VERSION ""

NS_ :

BS_:

BU_: GW_ABFD ADCU3_ABFD

BO_ 563 ADCU3A_IMU: 16 ADCU3_ABFD
 SG_ ADCU3A_RollRateVld : 120|1@1+ (1,0) [0|1] "" Vector__XXX
 SG_ ADCU3A_PitchRateVld : 121|1@1+ (1,0) [0|1] "" Vector__XXX
 SG_ ADCU3A_YawRateVld : 122|1@1+ (1,0) [0|1] "" Vector__XXX

BO_ 1523 ADCU3A_Test: 64 ADCU3_ABFD
 SG_ ADCU3A_LKASFltCod : 0|16@1+ (1,0) [0|65535] "" Vector__XXX
 SG_ ADCU3A_LKARunLvl : 16|3@1+ (1,0) [0|4] "" Vector__XXX
 SG_ ADCU3A_LKALatSt : 19|3@1+ (1,0) [0|4] "bit" Vector__XXX
 SG_ ADCU3A_LKALaneWidth : 24|8@1+ (0.01,0) [0|25] "m" Vector__XXX
 SG_ ADCU3A_LKALeftVeh2CentrLeftLane : 32|16@1- (0.00390625,0) [-127|128] "m" Vector__XXX
 SG_ ADCU3A_LKARightVeh2CentrtLane : 48|16@1- (0.00390625,0) [-127|128] "m" Vector__XXX
 SG_ ADCU3A_LKALgtdPwDst : 64|15@1+ (0.00390625,0) [0|127.996] "m" Vector__XXX
 SG_ ADCU3A_LKALeftLatPwDst : 80|16@1- (0.00390625,0) [-127|128] "m" Vector__XXX
 SG_ ADCU3A_LKARightLatPwDst : 96|16@1- (0.00390625,0) [-127|128] "m" Vector__XXX
 SG_ ADCU3A_LKACalcTarCrvt : 112|16@1- (9.8E-007,0.031999023) [-0.02|0.02] "1/m" Vector__XXX
 SG_ ADCU3A_BSDFaultCode : 128|16@1+ (1,0) [0|65535] "" Vector__XXX
 SG_ ADCU3A_DOWFaultCode : 144|16@1+ (1,0) [0|65535] "" Vector__XXX
 SG_ ADCU3A_ISLIFaultCode : 160|16@1+ (1,0) [0|65535] "" Vector__XXX
 SG_ ADCU3A_FCWInhibitNum : 176|16@1+ (1,0) [0|65535] "bit" Vector__XXX
 SG_ ADCU3A_FCWMode : 192|4@1+ (1,0) [0|15] "bit" Vector__XXX
 SG_ ADCU3A_FCW1Dist : 198|10@1+ (0.1,0) [0|100] "m" Vector__XXX
 SG_ ADCU3A_FCW2Dist : 208|10@1+ (0.1,0) [0|100] "m" Vector__XXX
 SG_ ADCU3A_FCW3Dist : 222|10@1+ (0.1,0) [0|100] "m" Vector__XXX
 SG_ ADCU3A_FCWAvoidAcc : 232|8@1+ (0.1,-10) [-10|10] "m/s^2" Vector__XXX
 SG_ ADCU3A_AEBInhibitNum : 240|16@1+ (1,0) [0|65535] "" Vector__XXX
 SG_ ADCU3A_AEBMode : 256|4@1+ (1,0) [0|15] "" Vector__XXX
 SG_ ADCU3A_AEBDist : 262|10@1+ (0.1,0) [0|100] "m" Vector__XXX
 SG_ ADCU3A_FCWCIP : 272|4@1+ (1,0) [0|15] "" Vector__XXX
 SG_ ADCU3A_FCWTargetID : 280|8@1+ (1,0) [0|255] "" Vector__XXX
 SG_ ADCU3A_FCWRelDisX : 288|11@1+ (0.1,0) [0|204.7] "m" Vector__XXX
 SG_ ADCU3A_FCWRelSpdX : 304|14@1+ (0.01,-81.92) [-81.92|81.91] "m/s" Vector__XXX
 SG_ ADCU3A_FCWOffset : 320|8@1+ (0.1,-12.7) [-12.7|12.8] "m" Vector__XXX
 SG_ ADCU3A_FCWRelDisY : 328|8@1+ (0.1,-12.7) [-12.7|12.8] "m" Vector__XXX
 SG_ ADCU3A_FCWRelSpdY : 336|8@1+ (0.1,-12.7) [-12.7|12.8] "m/s" Vector__XXX
 SG_ ADCU3A_AEBCIP : 344|4@1+ (1,0) [0|15] "" Vector__XXX
 SG_ ADCU3A_AEBTargetID : 352|8@1+ (1,0) [0|255] "" Vector__XXX
 SG_ ADCU3A_AEBRelDisX : 360|11@1+ (0.1,0) [0|204.7] "m" Vector__XXX
 SG_ ADCU3A_AEBRelSpdX : 376|14@1+ (0.01,-81.92) [-81.92|81.91] "m/s" Vector__XXX
 SG_ ADCU3A_AEBOffset : 392|8@1+ (0.1,-12.7) [-12.7|12.8] "m" Vector__XXX
 SG_ ADCU3A_AEBRelDisY : 400|8@1+ (0.1,-12.7) [-12.7|12.8] "m" Vector__XXX
 SG_ ADCU3A_AEBRelSpdY : 408|8@1+ (0.1,-12.7) [-12.7|12.8] "m/s" Vector__XXX

BO_ 2566877463 CDCU_BodyCtrl: 8 GW_ABFD
 SG_ CDCU_FrFogLgtSwt : 8|2@1+ (1,0) [0|3] ""  ADCU3_ABFD
 SG_ CDCU_ReFogLgtSwt : 10|2@1+ (1,0) [0|3] ""  ADCU3_ABFD

BO_ 1101 CDCU_St1: 16 GW_ABFD
 SG_ CDCU_VehSpdHMI : 32|13@1+ (0.1,0) [0|819.1] "km/h"  ADCU3_ABFD

BO_ 621 CDCU_ADCUCtrl: 16 GW_ABFD
 SG_ CDCU_ADCUCtrl_CRC : 0|16@1+ (1,0) [0|65535] ""  ADCU3_ABFD
 SG_ CDCU_ADCUCtrl_AC : 16|8@1+ (1,0) [0|255] ""  ADCU3_ABFD
 SG_ CDCU_FwdCllsnPrevnSwt : 24|1@1+ (1,0) [0|1] ""  ADCU3_ABFD
 SG_ CDCU_FwdCllsnPrevnMdSwt : 28|1@1+ (1,0) [0|1] ""  ADCU3_ABFD
 SG_ CDCU_FwdCllsnPrevnSnvtySet : 30|2@1+ (1,0) [0|3] ""  ADCU3_ABFD
 SG_ CDCU_ISLISwt : 32|1@1+ (1,0) [0|1] ""  ADCU3_ABFD
 SG_ CDCU_ISLISnvtySet : 34|5@1+ (1,-15) [-15|16] "km/h"  ADCU3_ABFD
 SG_ CDCU_LKASSwt : 42|1@1+ (1,0) [0|1] ""  ADCU3_ABFD
 SG_ CDCU_PACCSwt : 46|1@1+ (1,0) [0|1] ""  ADCU3_ABFD
 SG_ CDCU_HNASwt : 50|1@1+ (1,0) [0|1] ""  ADCU3_ABFD
 SG_ CDCU_FctLrngModSwt : 58|1@1+ (1,0) [0|1] ""  ADCU3_ABFD
 SG_ CDCU_FctLrngModSt : 60|2@1+ (1,0) [0|3] ""  ADCU3_ABFD
 SG_ CDCU_FctLrngModRes : 62|2@1+ (1,0) [0|3] ""  ADCU3_ABFD
 SG_ CDCU_HISSnsrAutoClrSwt : 64|1@1+ (1,0) [0|1] ""  ADCU3_ABFD
 SG_ CDCU_HISSnsrClrSwt : 66|4@1+ (1,0) [0|15] ""  ADCU3_ABFD
 SG_ CDCU_BSDSwt : 72|1@1+ (1,0) [0|1] ""  ADCU3_ABFD
 SG_ CDCU_DOWSwt : 73|1@1+ (1,0) [0|1] ""  ADCU3_ABFD
 SG_ CDCU_LKASFuncSetSwt : 76|1@1+ (1,0) [0|1] ""  ADCU3_ABFD
 SG_ CDCU_LKASWarnFormSetSwt : 77|2@1+ (1,0) [0|3] ""  ADCU3_ABFD
 SG_ CDCU_LKASSnvtySetSwt : 80|2@1+ (1,0) [0|3] ""  ADCU3_ABFD
 SG_ CDCU_LaneChgSwt : 82|1@1+ (1,0) [0|1] ""  ADCU3_ABFD
 SG_ CDCU_AutoLaneChgCfm : 83|1@1+ (1,0) [0|1] ""  ADCU3_ABFD
 SG_ CDCU_AutoLaneChgRmnSet : 84|2@1+ (1,0) [0|3] ""  ADCU3_ABFD
 SG_ CDCU_AutoLaneChgSet : 86|2@1+ (1,0) [0|3] ""  ADCU3_ABFD
 SG_ CDCU_NightVisnSwt : 88|1@1+ (1,0) [0|1] ""  ADCU3_ABFD
 SG_ CDCU_NightVisnWarnModReq : 90|2@1+ (1,0) [0|3] ""  ADCU3_ABFD

BO_ 1230 CDCU_DMSSt: 16 GW_ABFD
 SG_ CDCU_DMSSet_CRC : 0|16@1+ (1,0) [0|65535] ""  ADCU3_ABFD
 SG_ CDCU_DMSSet_AC : 16|8@1+ (1,0) [0|255] ""  ADCU3_ABFD
 SG_ CDCU_DMSSt : 24|3@1+ (1,0) [0|7] ""  ADCU3_ABFD
 SG_ CDCU_DMSErrSt : 64|2@1+ (1,0) [0|3] ""  ADCU3_ABFD
 SG_ CDCU_DMSWarnSwt : 66|1@1+ (1,0) [0|1] ""  ADCU3_ABFD
 SG_ CDCU_DrvrFatgWarn : 68|2@1+ (1,0) [0|3] ""  ADCU3_ABFD
 SG_ CDCU_AbnoActnDtcn : 72|3@1+ (1,0) [0|7] ""  ADCU3_ABFD
 SG_ CDCU_AbnoEmtnDtcn : 75|3@1+ (1,0) [0|7] ""  ADCU3_ABFD
 SG_ CDCU_DistrctnWarn : 80|3@1+ (1,0) [0|7] ""  ADCU3_ABFD

BO_ 2566832407 CDCU_VDHR: 8 GW_ABFD
 SG_ CDCU_VehTotDst : 0|32@1+ (1,0) [0|10000000] "kM"  ADCU3_ABFD

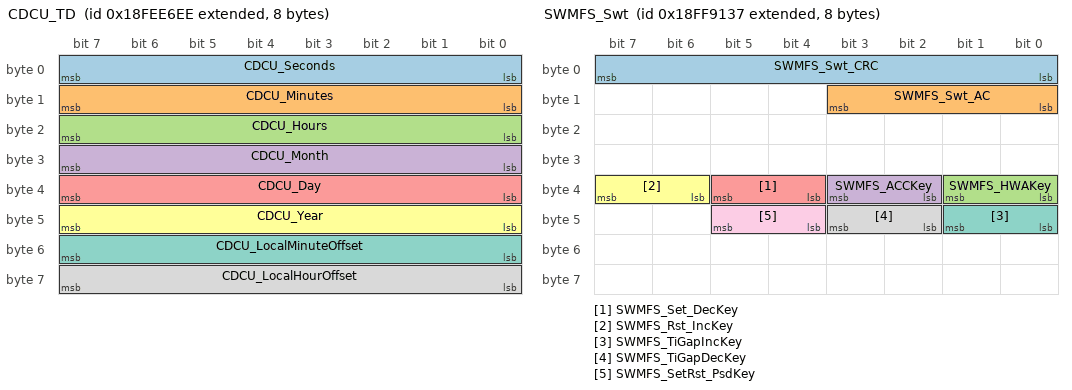
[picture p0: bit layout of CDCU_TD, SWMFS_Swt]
BO_ 2566842094 CDCU_TD: 8 GW_ABFD
 SG_ CDCU_Seconds : 0|8@1+ (0.25,0) [0|59.75] "s"  ADCU3_ABFD
 SG_ CDCU_Minutes : 8|8@1+ (1,0) [0|59] "min"  ADCU3_ABFD
 SG_ CDCU_Hours : 16|8@1+ (1,0) [0|23] "h"  ADCU3_ABFD
 SG_ CDCU_Month : 24|8@1+ (1,0) [1|12] "month"  ADCU3_ABFD
 SG_ CDCU_Day : 32|8@1+ (0.25,0) [0.25|31.75] "day"  ADCU3_ABFD
 SG_ CDCU_Year : 40|8@1+ (1,1985) [1985|2235] "year"  ADCU3_ABFD
 SG_ CDCU_LocalMinuteOffset : 48|8@1+ (1,-59) [-59|59] "min"  ADCU3_ABFD
 SG_ CDCU_LocalHourOffset : 56|8@1+ (1,-23) [-23|23] "h"  ADCU3_ABFD

BO_ 2566885687 SWMFS_Swt: 8 GW_ABFD
 SG_ SWMFS_Swt_CRC : 0|8@1+ (1,0) [0|255] ""  ADCU3_ABFD
 SG_ SWMFS_Swt_AC : 8|4@1+ (1,0) [0|14] ""  ADCU3_ABFD
 SG_ SWMFS_HWAKey : 32|2@1+ (1,0) [0|3] ""  ADCU3_ABFD
 SG_ SWMFS_ACCKey : 34|2@1+ (1,0) [0|3] ""  ADCU3_ABFD
 SG_ SWMFS_Set_DecKey : 36|2@1+ (1,0) [0|3] ""  ADCU3_ABFD
 SG_ SWMFS_Rst_IncKey : 38|2@1+ (1,0) [0|3] ""  ADCU3_ABFD
 SG_ SWMFS_TiGapIncKey : 40|2@1+ (1,0) [0|3] ""  ADCU3_ABFD
 SG_ SWMFS_TiGapDecKey : 42|2@1+ (1,0) [0|3] ""  ADCU3_ABFD
 SG_ SWMFS_SetRst_PsdKey : 44|2@1+ (1,0) [0|3] ""  ADCU3_ABFD

BO_ 2015 StdFunc_DiagReq: 8 GW_ABFD
 SG_ StdFunc_DiagReqData : 0|64@1+ (1,0) [0|9.22337203685477E+018] ""  ADCU3_ABFD

BO_ 1065 TBOX_RmtCtrl2: 16 GW_ABFD

BO_ 1793 FR_DiagReq: 64 GW_ABFD

BO_ 1801 FR_DiagResp: 64 ADCU3_ABFD

BO_ 1926 CR_FL_DiagReq: 64 GW_ABFD

BO_ 1934 CR_FL_DiagResp: 64 ADCU3_ABFD

BO_ 1927 CR_FR_DiagReq: 64 GW_ABFD

BO_ 1935 CR_FR_DiagResp: 64 ADCU3_ABFD

BO_ 1936 CR_RL_DiagReq: 64 GW_ABFD

BO_ 1944 CR_RL_DiagResp: 64 ADCU3_ABFD

BO_ 1925 CR_RR_DiagReq: 64 GW_ABFD

BO_ 1933 CR_RR_DiagResp: 64 ADCU3_ABFD

CM_ SG_ 563 ADCU3A_RollRateVld "Roll Rate Validity
IMU侧倾角速度有效性";
CM_ SG_ 563 ADCU3A_PitchRateVld "Pitch Rate Validity
IMU俯仰角速度有效性";
CM_ SG_ 563 ADCU3A_YawRateVld "Yaw Rate Validity
IMU横摆角速度有效性";
CM_ SG_ 1523 ADCU3A_LKASFltCod "LKAS fault code
LKAS故障码";
CM_ SG_ 1523 ADCU3A_LKARunLvl "LKA operation status level
LKA运行状态等级";
CM_ SG_ 1523 ADCU3A_LKALatSt "Vehicle lateral motion state
车辆横向运动状态";
CM_ SG_ 1523 ADCU3A_LKALaneWidth "Lane width
车道宽度";
CM_ SG_ 1523 ADCU3A_LKALeftVeh2CentrLeftLane "Distance between vehicle and lane center calculated by left lane line
从左侧车道线计算的车辆距车道中心位置";
CM_ SG_ 1523 ADCU3A_LKARightVeh2CentrtLane "从右侧车道线计算的车辆距车道中心位置";
CM_ SG_ 1523 ADCU3A_LKALgtdPwDst "预瞄点纵向距离";
CM_ SG_ 1523 ADCU3A_LKALeftLatPwDst "从左侧车道线计算的预瞄点横向距离";
CM_ SG_ 1523 ADCU3A_LKARightLatPwDst "从右侧车道线计算的预瞄点横向距离";
CM_ SG_ 1523 ADCU3A_LKACalcTarCrvt "计算的目标曲率";
CM_ SG_ 1523 ADCU3A_BSDFaultCode "BSD Fault Code
BSD故障码";
CM_ SG_ 1523 ADCU3A_DOWFaultCode "DOW Fault Code
DOW故障码";
CM_ SG_ 1523 ADCU3A_ISLIFaultCode "ISLI Fault Code
ISLI故障码";
CM_ SG_ 1523 ADCU3A_FCWInhibitNum "FCW抑制代码";
CM_ SG_ 1523 ADCU3A_FCWMode "FCW工作模式";
CM_ SG_ 1523 ADCU3A_FCW1Dist "FCW一级报警距离";
CM_ SG_ 1523 ADCU3A_FCW2Dist "FCW二级报警距离";
CM_ SG_ 1523 ADCU3A_FCW3Dist "FCW三级报警距离";
CM_ SG_ 1523 ADCU3A_FCWAvoidAcc "避撞减速度";
CM_ SG_ 1523 ADCU3A_AEBInhibitNum "AEB抑制代码";
CM_ SG_ 1523 ADCU3A_AEBMode "AEB工作模式";
CM_ SG_ 1523 ADCU3A_AEBDist "AEB作用距离";
CM_ SG_ 1523 ADCU3A_FCWCIP "FCW目标序号";
CM_ SG_ 1523 ADCU3A_FCWTargetID "FCW目标ID";
CM_ SG_ 1523 ADCU3A_FCWRelDisX "FCW目标纵向相对距离";
CM_ SG_ 1523 ADCU3A_FCWRelSpdX "FCW目标纵向相对速度";
CM_ SG_ 1523 ADCU3A_FCWOffset "FCW目标横向偏移";
CM_ SG_ 1523 ADCU3A_FCWRelDisY "FCW目标横向相对距离";
CM_ SG_ 1523 ADCU3A_FCWRelSpdY "FCW目标横向相对速度";
CM_ SG_ 1523 ADCU3A_AEBCIP "AEB目标序号";
CM_ SG_ 1523 ADCU3A_AEBTargetID "AEB目标ID";
CM_ SG_ 1523 ADCU3A_AEBRelDisX "AEB目标纵向相对距离";
CM_ SG_ 1523 ADCU3A_AEBRelSpdX "AEB目标纵向相对速度";
CM_ SG_ 1523 ADCU3A_AEBOffset "AEB目标横向偏移";
CM_ SG_ 1523 ADCU3A_AEBRelDisY "AEB目标横向相对距离";
CM_ SG_ 1523 ADCU3A_AEBRelSpdY "AEB目标横向相对速度";
CM_ SG_ 2566877463 CDCU_FrFogLgtSwt "Front fog light switch command
前雾灯开关";
CM_ SG_ 2566877463 CDCU_ReFogLgtSwt "Rear fog light switch command
后雾灯开关";
CM_ SG_ 1101 CDCU_VehSpdHMI "Vehicle Speed on HMI 
显示车速";
CM_ SG_ 621 CDCU_ADCUCtrl_CRC "CRC16";
CM_ SG_ 621 CDCU_ADCUCtrl_AC "Alive Counter";
CM_ SG_ 621 CDCU_FwdCllsnPrevnSwt "Forward Collision Prevention  Switch
前向防撞辅助开关";
CM_ SG_ 621 CDCU_FwdCllsnPrevnMdSwt "Forward Collision Prevention Mode Switch
前向防撞辅助模式";
CM_ SG_ 621 CDCU_FwdCllsnPrevnSnvtySet "Forward Collision Prevention Sensitivity Set
前向防撞辅助灵敏度设置";
CM_ SG_ 621 CDCU_ISLISwt "ISLI switch
ISLI功能开关";
CM_ SG_ 621 CDCU_ISLISnvtySet "ISLI sensitivity set
ISLI功能灵敏设置";
CM_ SG_ 621 CDCU_LKASSwt "LKAS switch
LKAS功能开关";
CM_ SG_ 621 CDCU_PACCSwt "PACC switch
PACC功能开关";
CM_ SG_ 621 CDCU_HNASwt "HNA switch
高速公路导航辅助功能开关";
CM_ SG_ 621 CDCU_FctLrngModSwt "Function learning mode switch
功能学习模式开关";
CM_ SG_ 621 CDCU_FctLrngModSt "Function learning mode state
功能学习模式状态";
CM_ SG_ 621 CDCU_FctLrngModRes "Function learning mode result
功能学习模式结果";
CM_ SG_ 621 CDCU_HISSnsrAutoClrSwt "HIS sensor auto clear switch
智能驾驶自动清洗开关";
CM_ SG_ 621 CDCU_HISSnsrClrSwt "HIS sensor clear switch
智能驾驶传感器清洗开关";
CM_ SG_ 621 CDCU_BSDSwt "BSD switch
BSD功能开关";
CM_ SG_ 621 CDCU_DOWSwt "DOW switch
DOW功能开关";
CM_ SG_ 621 CDCU_LKASFuncSetSwt "LKAS Function Set
LKAS辅助等级设置";
CM_ SG_ 621 CDCU_LKASWarnFormSetSwt "LKAS Warnning Form Set
LKAS提醒方式设置";
CM_ SG_ 621 CDCU_LKASSnvtySetSwt "LKAS Snvty Set
LKAS灵敏度设置";
CM_ SG_ 621 CDCU_LaneChgSwt "Lane change auxiliary switch
变道辅助开关";
CM_ SG_ 621 CDCU_AutoLaneChgCfm "Automatic lane change confirmation switch
自动变道确认开关反馈";
CM_ SG_ 621 CDCU_AutoLaneChgRmnSet "Lane change reminder setting
变道提醒设置";
CM_ SG_ 621 CDCU_AutoLaneChgSet "Lane change style setting
变道风格设置反馈";
CM_ SG_ 621 CDCU_NightVisnSwt "Night Vision Switch
夜视辅助开关";
CM_ SG_ 621 CDCU_NightVisnWarnModReq "Night Vision Warning Mode Request
夜视辅助报警模式请求";
CM_ SG_ 1230 CDCU_DMSSet_CRC "CRC16";
CM_ SG_ 1230 CDCU_DMSSet_AC "Alive Counter";
CM_ SG_ 1230 CDCU_DMSSt "DMS system state
DMS系统状态";
CM_ SG_ 1230 CDCU_DMSErrSt "DMS fault state
DMS故障状态";
CM_ SG_ 1230 CDCU_DMSWarnSwt "DMS warning switch state (reserved)
DMS报警开关状态（预留）";
CM_ SG_ 1230 CDCU_DrvrFatgWarn "Driver fatigue warn
主驾疲劳报警";
CM_ SG_ 1230 CDCU_AbnoActnDtcn "Driver abnormal behavior detected
主驾异常行为监测";
CM_ SG_ 1230 CDCU_AbnoEmtnDtcn "Driver abnormal emotion detected
主驾异常情绪监测";
CM_ SG_ 1230 CDCU_DistrctnWarn "Driver attention warning
主驾注意力报警";
CM_ SG_ 2566832407 CDCU_VehTotDst "Vehicle total distance
整车总里程";
CM_ SG_ 2566842094 CDCU_Seconds "Seconds
秒";
CM_ SG_ 2566842094 CDCU_Minutes "Minutes
分";
CM_ SG_ 2566842094 CDCU_Hours "Hours
时";
CM_ SG_ 2566842094 CDCU_Month "Month
月";
CM_ SG_ 2566842094 CDCU_Day "Day
日";
CM_ SG_ 2566842094 CDCU_Year "Year
年";
CM_ SG_ 2566842094 CDCU_LocalMinuteOffset "Local minute offset
本地分钟偏差";
CM_ SG_ 2566842094 CDCU_LocalHourOffset "Local hour offset
本地小时偏移";
CM_ SG_ 2566885687 SWMFS_Swt_CRC "CRC8";
CM_ SG_ 2566885687 SWMFS_Swt_AC "Alive Counter";
CM_ SG_ 2566885687 SWMFS_HWAKey "HWA switch
HWA开关";
CM_ SG_ 2566885687 SWMFS_ACCKey "ACC switch
ACC开关";
CM_ SG_ 2566885687 SWMFS_Set_DecKey "Set- switch
Set-开关";
CM_ SG_ 2566885687 SWMFS_Rst_IncKey "Reset+ switch
Reset+开关";
CM_ SG_ 2566885687 SWMFS_TiGapIncKey "Time gap increase switch
时距加开关";
CM_ SG_ 2566885687 SWMFS_TiGapDecKey "Time gap decrease switch
时距减开关";
CM_ SG_ 2566885687 SWMFS_SetRst_PsdKey "Intelligent speed limit confirmation switch
智能限速确认开关";
CM_ BO_ 2015 "OBD接口通过以太网TX或TBOX通过T1发送到GW，GW转换为CAN(FD)或以太网T1后向相应网段发送";
CM_ SG_ 2015 StdFunc_DiagReqData "诊断数据";
BA_DEF_ BO_  "DiagState" ENUM  "No","Yes";
BA_DEF_ BO_  "GenMsgSendType" ENUM  "Cyclic","Event","IfActive","CE","CA","NoMsgSendType";
BA_DEF_ BO_  "GenMsgCycleTime" INT 0 0;
BA_DEF_ SG_  "GenSigSendType" ENUM  "Cyclic","OnChange","OnWrite","IfActive","OnChangeWithRepetition","OnWriteWithRepetition","IfActiveWithRepetition","NoSigSendType","OnChangeAndIfActive","OnChangeAndIfActiveWithRepetition","CA","CE","Event";
BA_DEF_ SG_  "GenSigStartValue" INT 0 0;
BA_DEF_ BO_  "GenMsgCycleTimeFast" INT 0 0;
BA_DEF_ BO_  "CANFD_BRS" ENUM  "0","1";
BA_DEF_ BO_  "VFrameFormat" ENUM  "StandardCAN","ExtendedCAN","reserved","reserved","reserved","reserved","reserved","reserved","reserved","reserved","reserved","reserved","reserved","reserved","StandardCAN_FD","ExtendedCAN_FD";
BA_DEF_DEF_  "DiagState" "No";
BA_DEF_DEF_  "GenMsgSendType" "Cyclic";
BA_DEF_DEF_  "GenMsgCycleTime" 0;
BA_DEF_DEF_  "GenSigSendType" "Cyclic";
BA_DEF_DEF_  "GenSigStartValue" 0;
BA_DEF_DEF_  "GenMsgCycleTimeFast" 0;
BA_DEF_DEF_  "CANFD_BRS" "1";
BA_DEF_DEF_  "VFrameFormat" "StandardCAN_FD";
BA_ "GenMsgCycleTimeFast" BO_ 1523 20;
BA_ "GenMsgCycleTime" BO_ 1523 20;
BA_ "GenMsgCycleTime" BO_ 2566877463 100;
BA_ "VFrameFormat" BO_ 2566877463 15;
BA_ "GenMsgCycleTime" BO_ 1101 200;
BA_ "GenMsgCycleTime" BO_ 621 50;
BA_ "GenMsgCycleTime" BO_ 1230 500;
BA_ "GenMsgCycleTime" BO_ 2566832407 1000;
BA_ "VFrameFormat" BO_ 2566832407 15;
BA_ "GenMsgCycleTime" BO_ 2566842094 1000;
BA_ "VFrameFormat" BO_ 2566842094 15;
BA_ "GenMsgCycleTime" BO_ 2566885687 100;
BA_ "VFrameFormat" BO_ 2566885687 15;
BA_ "GenMsgSendType" BO_ 2015 1;
BA_ "DiagState" BO_ 2015 1;
BA_ "GenMsgCycleTime" BO_ 1065 200;
BA_ "GenMsgSendType" BO_ 1793 1;
BA_ "GenMsgSendType" BO_ 1801 1;
BA_ "GenMsgSendType" BO_ 1926 1;
BA_ "GenMsgSendType" BO_ 1934 1;
BA_ "GenMsgSendType" BO_ 1927 1;
BA_ "GenMsgSendType" BO_ 1935 1;
BA_ "GenMsgSendType" BO_ 1936 1;
BA_ "GenMsgSendType" BO_ 1944 1;
BA_ "GenMsgSendType" BO_ 1925 1;
BA_ "GenMsgSendType" BO_ 1933 1;
BA_ "GenSigStartValue" SG_ 621 CDCU_FwdCllsnPrevnSwt 1;
BA_ "GenSigStartValue" SG_ 621 CDCU_FwdCllsnPrevnMdSwt 1;
BA_ "GenSigStartValue" SG_ 621 CDCU_ISLISnvtySet 15;
BA_ "GenSigStartValue" SG_ 621 CDCU_LKASSwt 1;
BA_ "GenSigSendType" SG_ 2015 StdFunc_DiagReqData 2;
VAL_ 563 ADCU3A_RollRateVld 1 "Valid" 0 "Invalid" ;
VAL_ 563 ADCU3A_PitchRateVld 1 "Valid" 0 "Invalid" ;
VAL_ 563 ADCU3A_YawRateVld 1 "Valid" 0 "Invalid" ;
VAL_ 2566877463 CDCU_FrFogLgtSwt 3 "Reserved" 2 "ON" 1 "OFF" 0 "No request" ;
VAL_ 2566877463 CDCU_ReFogLgtSwt 3 "Reserved" 2 "ON" 1 "OFF" 0 "No request" ;
VAL_ 1101 CDCU_VehSpdHMI 8191 "Invalid" ;
VAL_ 621 CDCU_FwdCllsnPrevnSwt 1 "On" 0 "Off" ;
VAL_ 621 CDCU_FwdCllsnPrevnMdSwt 1 "AEB On" 0 "FCW On" ;
VAL_ 621 CDCU_FwdCllsnPrevnSnvtySet 3 "reserved" 2 "Low Sensitivity" 1 "High Sensitivity" 0 "Normal" ;
VAL_ 621 CDCU_ISLISwt 1 "On" 0 "Off" ;
VAL_ 621 CDCU_ISLISnvtySet 31 "Invalid" 30 "Valid" 29 "Valid" 28 "Valid" 27 "Valid" 26 "Valid" 25 "Valid" 24 "Valid" 23 "Valid" 22 "Valid" 21 "Valid" 20 "Valid" 19 "Valid" 18 "Valid" 17 "Valid" 16 "Valid" 15 "Valid" 14 "Valid" 13 "Valid" 12 "Valid" 11 "Valid" 10 "Valid" 9 "Valid" 8 "Valid" 7 "Valid" 6 "Valid" 5 "Valid" 4 "Valid" 3 "Valid" 2 "Valid" 1 "Valid" 0 "Valid" ;
VAL_ 621 CDCU_LKASSwt 1 "On" 0 "Off" ;
VAL_ 621 CDCU_PACCSwt 1 "On" 0 "Off" ;
VAL_ 621 CDCU_HNASwt 1 "On" 0 "Off" ;
VAL_ 621 CDCU_FctLrngModSwt 1 "On" 0 "Off" ;
VAL_ 621 CDCU_FctLrngModSt 3 "Reserved" 2 "Learned" 1 "Learning" 0 "No Learn" ;
VAL_ 621 CDCU_FctLrngModRes 3 "Reserved" 2 "Pass" 1 "Fault" 0 "No learn" ;
VAL_ 621 CDCU_HISSnsrAutoClrSwt 1 "On" 0 "Off" ;
VAL_ 621 CDCU_HISSnsrClrSwt 15 "Reserved" 14 "Reserved" 13 "Reserved" 12 "Reserved" 11 "Reserved" 10 "Reserved" 9 "Reserved" 8 "Reserved" 7 "Reserved" 6 "Reserved" 5 "Reserved" 4 "Reserved" 3 "Reserved" 2 "Reserved" 1 "Lidar Clear" 0 "No Demand" ;
VAL_ 621 CDCU_BSDSwt 1 "On" 0 "Off" ;
VAL_ 621 CDCU_DOWSwt 1 "On" 0 "Off" ;
VAL_ 621 CDCU_LKASFuncSetSwt 1 "LKA on" 0 "LDW on" ;
VAL_ 621 CDCU_LKASWarnFormSetSwt 3 "Reserved" 2 "Voice+Haptic" 1 "Haptic" 0 "Voice" ;
VAL_ 621 CDCU_LKASSnvtySetSwt 3 "Reserved" 2 "Low Sensitivity" 1 "High Sensitivity" 0 "Normal" ;
VAL_ 621 CDCU_LaneChgSwt 1 "On" 0 "Off" ;
VAL_ 621 CDCU_AutoLaneChgCfm 1 "Confirmation" 0 "Not Confirmation" ;
VAL_ 621 CDCU_AutoLaneChgRmnSet 3 "Reserved" 2 "Sound" 1 "Beep" 0 "Off" ;
VAL_ 621 CDCU_AutoLaneChgSet 3 "Reserved" 2 "High Sensitivity" 1 "Normal" 0 "Low Sensitivity" ;
VAL_ 621 CDCU_NightVisnSwt 1 "On" 0 "Off" ;
VAL_ 621 CDCU_NightVisnWarnModReq 3 "Reserved" 2 "Pedestrian and Animal Warning" 1 "Pedestrian Warning" 0 "No Warning" ;
VAL_ 1230 CDCU_DMSSt 7 "Reserved" 6 "Reserved" 5 "Reserved" 4 "Reserved" 3 "Error" 2 "System monitoring driver behavior" 1 "System Available" 0 "Initializing" ;
VAL_ 1230 CDCU_DMSErrSt 2 "Fault" 1 "Blocking" 0 "Normal" ;
VAL_ 1230 CDCU_DMSWarnSwt 1 "On" 0 "Off" ;
VAL_ 1230 CDCU_DrvrFatgWarn 3 "Level3" 2 "Level2" 1 "Level1" 0 "No Warning" ;
VAL_ 1230 CDCU_AbnoActnDtcn 7 "Reserved" 6 "Reserved" 5 "Reserved" 4 "Wear sunglasses" 3 "Not recognized" 2 "Smoking" 1 "Calling" 0 "No Abnormal Action" ;
VAL_ 1230 CDCU_AbnoEmtnDtcn 7 "Reserved" 6 "Fear" 5 "Anger" 4 "Pain" 3 "Excitement" 2 "Excessive loss" 1 "Excessive happiness" 0 "No Abnormal emtion" ;
VAL_ 1230 CDCU_DistrctnWarn 7 "Reserved" 6 "Reserved" 5 "Reserved" 4 "Other Warning" 3 "Down Warning" 2 "Right Warning" 1 "Left Warning" 0 "No Warning" ;
VAL_ 2566832407 CDCU_VehTotDst -2147483648 "Invalid" ;
VAL_ 2566842094 CDCU_Seconds 255 "Invalid" ;
VAL_ 2566842094 CDCU_Minutes 255 "Invalid" ;
VAL_ 2566842094 CDCU_Hours 255 "Invalid" ;
VAL_ 2566842094 CDCU_Month 255 "Invalid" ;
VAL_ 2566842094 CDCU_Day 255 "Invalid" ;
VAL_ 2566842094 CDCU_Year 255 "Invalid" ;
VAL_ 2566885687 SWMFS_HWAKey 3 "Reserved" 2 "Error" 1 "Pressed" 0 "Not Pressed" ;
VAL_ 2566885687 SWMFS_ACCKey 3 "Reserved" 2 "Error" 1 "Pressed" 0 "Not Pressed" ;
VAL_ 2566885687 SWMFS_Set_DecKey 3 "Reserved" 2 "Error" 1 "Pressed" 0 "Not Pressed" ;
VAL_ 2566885687 SWMFS_Rst_IncKey 3 "Reserved" 2 "Error" 1 "Pressed" 0 "Not Pressed" ;
VAL_ 2566885687 SWMFS_TiGapIncKey 3 "Reserved" 2 "Error" 1 "Pressed" 0 "Not Pressed" ;
VAL_ 2566885687 SWMFS_TiGapDecKey 3 "Reserved" 2 "Error" 1 "Pressed" 0 "Not Pressed" ;
VAL_ 2566885687 SWMFS_SetRst_PsdKey 3 "Reserved" 2 "Error" 1 "Pressed" 0 "Not Pressed" ;
